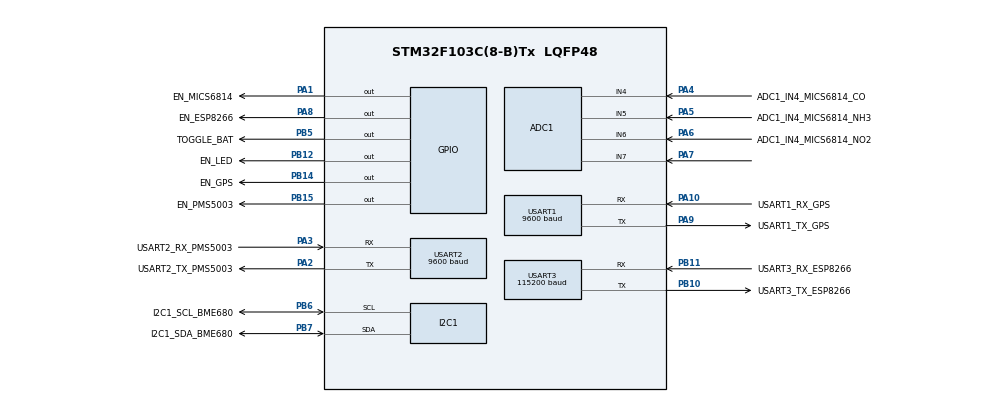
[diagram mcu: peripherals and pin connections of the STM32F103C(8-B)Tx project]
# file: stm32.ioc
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ADC1.Channel-0\#ChannelRegularConversion=ADC_CHANNEL_4
ADC1.Channel-1\#ChannelRegularConversion=ADC_CHANNEL_5
ADC1.Channel-2\#ChannelRegularConversion=ADC_CHANNEL_6
ADC1.Channel-3\#ChannelRegularConversion=ADC_CHANNEL_7
ADC1.Channel-6\#ChannelRegularConversion=ADC_CHANNEL_TEMPSENSOR
ADC1.Channel-7\#ChannelRegularConversion=ADC_CHANNEL_VREFINT
ADC1.ContinuousConvMode=ENABLE
ADC1.EnableAnalogWatchDog=false
ADC1.NbrOfConversion=6
ADC1.NbrOfConversionFlag=1
ADC1.Rank-0\#ChannelRegularConversion=1
ADC1.Rank-1\#ChannelRegularConversion=2
ADC1.Rank-2\#ChannelRegularConversion=3
ADC1.Rank-3\#ChannelRegularConversion=4
ADC1.Rank-6\#ChannelRegularConversion=5
ADC1.Rank-7\#ChannelRegularConversion=6
ADC1.SamplingTime-0\#ChannelRegularConversion=ADC_SAMPLETIME_239CYCLES_5
ADC1.SamplingTime-1\#ChannelRegularConversion=ADC_SAMPLETIME_239CYCLES_5
ADC1.SamplingTime-2\#ChannelRegularConversion=ADC_SAMPLETIME_239CYCLES_5
ADC1.SamplingTime-3\#ChannelRegularConversion=ADC_SAMPLETIME_239CYCLES_5
ADC1.SamplingTime-6\#ChannelRegularConversion=ADC_SAMPLETIME_239CYCLES_5
ADC1.SamplingTime-7\#ChannelRegularConversion=ADC_SAMPLETIME_239CYCLES_5
ADC1.master=1
Dma.ADC1.0.Direction=DMA_PERIPH_TO_MEMORY
Dma.ADC1.0.Instance=DMA1_Channel1
Dma.ADC1.0.MemDataAlignment=DMA_MDATAALIGN_WORD
Dma.ADC1.0.MemInc=DMA_MINC_ENABLE
Dma.ADC1.0.Mode=DMA_CIRCULAR
Dma.ADC1.0.PeriphDataAlignment=DMA_PDATAALIGN_HALFWORD
Dma.ADC1.0.PeriphInc=DMA_PINC_DISABLE
Dma.ADC1.0.Priority=DMA_PRIORITY_LOW
Dma.Request0=ADC1
I2C1.I2C_Mode=I2C_Standard
Mcu.Family=STM32F1
Mcu.Name=STM32F103C(8-B)Tx
Mcu.Package=LQFP48
NVIC.DMA1_Channel1_IRQn=true\:0\:0\:false\:false\:true\:false\:true
NVIC.PriorityGroup=NVIC_PRIORITYGROUP_4
NVIC.RTC_Alarm_IRQn=true\:0\:0\:false\:false\:true\:true\:true
NVIC.TIM1_UP_IRQn=true\:0\:0\:false\:false\:true\:false\:true
NVIC.TimeBase=TIM1_UP_IRQn
NVIC.TimeBaseIP=TIM1
PA1.GPIO_Label=EN_MICS6814
PA1.Signal=GPIO_Output
PA10.GPIO_Label=USART1_RX_GPS
PA10.Mode=Asynchronous
PA10.Signal=USART1_RX
PA2.GPIO_Label=USART2_TX_PMS5003
PA2.Mode=Asynchronous
PA2.Signal=USART2_TX
PA3.GPIO_Label=USART2_RX_PMS5003
PA3.Mode=Asynchronous
PA3.Signal=USART2_RX
PA4.GPIO_Label=ADC1_IN4_MICS6814_CO
PA4.Signal=ADCx_IN4
PA5.GPIO_Label=ADC1_IN4_MICS6814_NH3
PA5.Signal=ADCx_IN5
PA6.GPIO_Label=ADC1_IN4_MICS6814_NO2
PA6.Signal=ADCx_IN6
PA7.Signal=ADCx_IN7
PA8.GPIO_Label=EN_ESP8266
PA8.Signal=GPIO_Output
PA9.GPIO_Label=USART1_TX_GPS
PA9.Mode=Asynchronous
PA9.Signal=USART1_TX
PB10.GPIO_Label=USART3_TX_ESP8266
PB10.Mode=Asynchronous
PB10.Signal=USART3_TX
PB11.GPIO_Label=USART3_RX_ESP8266
PB11.Mode=Asynchronous
PB11.Signal=USART3_RX
PB12.GPIO_Label=EN_LED
PB12.PinState=GPIO_PIN_SET
PB12.Signal=GPIO_Output
PB14.GPIO_Label=EN_GPS
PB14.Signal=GPIO_Output
PB15.GPIO_Label=EN_PMS5003
PB15.Signal=GPIO_Output
PB5.GPIO_Label=TOGGLE_BAT
PB5.Signal=GPIO_Output
PB6.GPIO_Label=I2C1_SCL_BME680
PB6.Mode=I2C
PB6.Signal=I2C1_SCL
PB7.GPIO_Label=I2C1_SDA_BME680
PB7.Mode=I2C
PB7.Signal=I2C1_SDA
ProjectManager.HeapSize=0x200
ProjectManager.StackSize=0x400
ProjectManager.TargetToolchain=Makefile
RCC.AHBCLKDivider=RCC_SYSCLK_DIV2
RCC.AHBFreq_Value=4000000
RCC.APB1CLKDivider=RCC_HCLK_DIV2
RCC.APB1Freq_Value=2000000
RCC.APB1TimFreq_Value=4000000
RCC.APB2Freq_Value=4000000
RCC.APB2TimFreq_Value=4000000
RCC.HCLKFreq_Value=4000000
RCC.SYSCLKFreq_VALUE=8000000
RCC.USBFreq_Value=8000000
RTC.Format=RTC_FORMAT_BIN
SH.ADCx_IN4.0=ADC1_IN4,IN4
SH.ADCx_IN5.0=ADC1_IN5,IN5
SH.ADCx_IN6.0=ADC1_IN6,IN6
SH.ADCx_IN7.0=ADC1_IN7,IN7
USART1.BaudRate=9600
USART1.VirtualMode=VM_ASYNC
USART2.BaudRate=9600
USART2.VirtualMode=VM_ASYNC
USART3.BaudRate=115200
USART3.Mode=MODE_TX_RX
USART3.VirtualMode=VM_ASYNC
VP_ADC1_TempSens_Input.Mode=IN-TempSens
VP_ADC1_Vref_Input.Mode=IN-Vrefint
VP_RTC_No_RTC_Output.Mode=RTC_OUT_NO
VP_RTC_VS_RTC_Activate.Mode=RTC_Enabled
VP_SYS_VS_ND.Mode=No_Debug
VP_SYS_VS_tim1.Mode=TIM1
board=custom

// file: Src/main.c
/* USER CODE BEGIN Header */
/**
  ******************************************************************************
  * @file           : main.c
  * @brief          : Main program body
  ******************************************************************************
  * @attention
  *
  * <h2><center>&copy; Copyright (c) 2020 STMicroelectronics.
  * All rights reserved.</center></h2>
  *
  * This software component is licensed by ST under Ultimate Liberty license
  * SLA0044, the "License"; You may not use this file except in compliance with
  * the License. You may obtain a copy of the License at:
  *                             www.st.com/SLA0044
  *
  ******************************************************************************
  */
/* USER CODE END Header */

#include "main.h"

/* USER CODE BEGIN Includes */
#include "run.h"
/* USER CODE END Includes */

ADC_HandleTypeDef hadc1;
DMA_HandleTypeDef hdma_adc1;

I2C_HandleTypeDef hi2c1;

RTC_HandleTypeDef hrtc;

UART_HandleTypeDef huart1;
UART_HandleTypeDef huart2;
UART_HandleTypeDef huart3;

void SystemClock_Config(void);
static void MX_GPIO_Init(void);
static void MX_DMA_Init(void);
static void MX_ADC1_Init(void);
static void MX_I2C1_Init(void);
static void MX_USART1_UART_Init(void);
static void MX_USART2_UART_Init(void);
static void MX_USART3_UART_Init(void);
static void MX_RTC_Init(void);

int main(void)
{

  /* MCU Configuration--------------------------------------------------------*/

  /* Reset of all peripherals, Initializes the Flash interface and the Systick. */
  HAL_Init();

  /* Configure the system clock */
  SystemClock_Config();

  /* Initialize all configured peripherals */
  MX_GPIO_Init();
  MX_DMA_Init();
  MX_ADC1_Init();
  MX_I2C1_Init();
  MX_USART1_UART_Init();
  MX_USART2_UART_Init();
  MX_USART3_UART_Init();
  MX_RTC_Init();

  /* Infinite loop */
  /* USER CODE BEGIN WHILE */
  setup();
  while (1)
  {
    loop();
    /* USER CODE END WHILE */

  }
}

void SystemClock_Config(void)
{
  LL_FLASH_SetLatency(LL_FLASH_LATENCY_0);

  if(LL_FLASH_GetLatency() != LL_FLASH_LATENCY_0)
  {
    Error_Handler();
  }
  LL_RCC_HSI_SetCalibTrimming(16);
  LL_RCC_HSI_Enable();

   /* Wait till HSI is ready */
  while(LL_RCC_HSI_IsReady() != 1)
  {

  }
  LL_RCC_LSI_Enable();

   /* Wait till LSI is ready */
  while(LL_RCC_LSI_IsReady() != 1)
  {

  }
  LL_PWR_EnableBkUpAccess();
  LL_RCC_ForceBackupDomainReset();
  LL_RCC_ReleaseBackupDomainReset();
  LL_RCC_SetRTCClockSource(LL_RCC_RTC_CLKSOURCE_LSI);
  LL_RCC_EnableRTC();
  LL_RCC_SetAHBPrescaler(LL_RCC_SYSCLK_DIV_2);
  LL_RCC_SetAPB1Prescaler(LL_RCC_APB1_DIV_2);
  LL_RCC_SetAPB2Prescaler(LL_RCC_APB2_DIV_1);
  LL_RCC_SetSysClkSource(LL_RCC_SYS_CLKSOURCE_HSI);

   /* Wait till System clock is ready */
  while(LL_RCC_GetSysClkSource() != LL_RCC_SYS_CLKSOURCE_STATUS_HSI)
  {

  }
  LL_SetSystemCoreClock(4000000);

   /* Update the time base */
  if (HAL_InitTick (TICK_INT_PRIORITY) != HAL_OK)
  {
    Error_Handler();
  };
  LL_RCC_SetADCClockSource(LL_RCC_ADC_CLKSRC_PCLK2_DIV_2);
}

static void MX_ADC1_Init(void)
{

  ADC_ChannelConfTypeDef sConfig = {0};

  /** Common config
  */
  hadc1.Instance = ADC1;
  hadc1.Init.ScanConvMode = ADC_SCAN_ENABLE;
  hadc1.Init.ContinuousConvMode = ENABLE;
  hadc1.Init.DiscontinuousConvMode = DISABLE;
  hadc1.Init.ExternalTrigConv = ADC_SOFTWARE_START;
  hadc1.Init.DataAlign = ADC_DATAALIGN_RIGHT;
  hadc1.Init.NbrOfConversion = 6;
  if (HAL_ADC_Init(&hadc1) != HAL_OK)
  {
    Error_Handler();
  }
  /** Configure Regular Channel
  */
  sConfig.Channel = ADC_CHANNEL_4;
  sConfig.Rank = ADC_REGULAR_RANK_1;
  sConfig.SamplingTime = ADC_SAMPLETIME_239CYCLES_5;
  if (HAL_ADC_ConfigChannel(&hadc1, &sConfig) != HAL_OK)
  {
    Error_Handler();
  }
  /** Configure Regular Channel
  */
  sConfig.Channel = ADC_CHANNEL_5;
  sConfig.Rank = ADC_REGULAR_RANK_2;
  if (HAL_ADC_ConfigChannel(&hadc1, &sConfig) != HAL_OK)
  {
    Error_Handler();
  }
  /** Configure Regular Channel
  */
  sConfig.Channel = ADC_CHANNEL_6;
  sConfig.Rank = ADC_REGULAR_RANK_3;
  if (HAL_ADC_ConfigChannel(&hadc1, &sConfig) != HAL_OK)
  {
    Error_Handler();
  }
  /** Configure Regular Channel
  */
  sConfig.Channel = ADC_CHANNEL_7;
  sConfig.Rank = ADC_REGULAR_RANK_4;
  if (HAL_ADC_ConfigChannel(&hadc1, &sConfig) != HAL_OK)
  {
    Error_Handler();
  }
  /** Configure Regular Channel
  */
  sConfig.Channel = ADC_CHANNEL_TEMPSENSOR;
  sConfig.Rank = ADC_REGULAR_RANK_5;
  if (HAL_ADC_ConfigChannel(&hadc1, &sConfig) != HAL_OK)
  {
    Error_Handler();
  }
  /** Configure Regular Channel
  */
  sConfig.Channel = ADC_CHANNEL_VREFINT;
  sConfig.Rank = ADC_REGULAR_RANK_6;
  if (HAL_ADC_ConfigChannel(&hadc1, &sConfig) != HAL_OK)
  {
    Error_Handler();
  }

}

static void MX_I2C1_Init(void)
{

  hi2c1.Instance = I2C1;
  hi2c1.Init.ClockSpeed = 100000;
  hi2c1.Init.DutyCycle = I2C_DUTYCYCLE_2;
  hi2c1.Init.OwnAddress1 = 0;
  hi2c1.Init.AddressingMode = I2C_ADDRESSINGMODE_7BIT;
  hi2c1.Init.DualAddressMode = I2C_DUALADDRESS_DISABLE;
  hi2c1.Init.OwnAddress2 = 0;
  hi2c1.Init.GeneralCallMode = I2C_GENERALCALL_DISABLE;
  hi2c1.Init.NoStretchMode = I2C_NOSTRETCH_DISABLE;
  if (HAL_I2C_Init(&hi2c1) != HAL_OK)
  {
    Error_Handler();
  }

}

static void MX_RTC_Init(void)
{

  RTC_TimeTypeDef sTime = {0};
  RTC_DateTypeDef DateToUpdate = {0};

  /** Initialize RTC Only
  */
  hrtc.Instance = RTC;
  hrtc.Init.AsynchPrediv = RTC_AUTO_1_SECOND;
  hrtc.Init.OutPut = RTC_OUTPUTSOURCE_NONE;
  if (HAL_RTC_Init(&hrtc) != HAL_OK)
  {
    Error_Handler();
  }

  /** Initialize RTC and set the Time and Date
  */
  sTime.Hours = 0;
  sTime.Minutes = 0;
  sTime.Seconds = 0;

  if (HAL_RTC_SetTime(&hrtc, &sTime, RTC_FORMAT_BIN) != HAL_OK)
  {
    Error_Handler();
  }
  DateToUpdate.WeekDay = RTC_WEEKDAY_MONDAY;
  DateToUpdate.Month = RTC_MONTH_JANUARY;
  DateToUpdate.Date = 1;
  DateToUpdate.Year = 0;

  if (HAL_RTC_SetDate(&hrtc, &DateToUpdate, RTC_FORMAT_BIN) != HAL_OK)
  {
    Error_Handler();
  }

}

static void MX_USART1_UART_Init(void)
{

  huart1.Instance = USART1;
  huart1.Init.BaudRate = 9600;
  huart1.Init.WordLength = UART_WORDLENGTH_8B;
  huart1.Init.StopBits = UART_STOPBITS_1;
  huart1.Init.Parity = UART_PARITY_NONE;
  huart1.Init.Mode = UART_MODE_TX_RX;
  huart1.Init.HwFlowCtl = UART_HWCONTROL_NONE;
  huart1.Init.OverSampling = UART_OVERSAMPLING_16;
  if (HAL_UART_Init(&huart1) != HAL_OK)
  {
    Error_Handler();
  }

}

static void MX_USART2_UART_Init(void)
{

  huart2.Instance = USART2;
  huart2.Init.BaudRate = 9600;
  huart2.Init.WordLength = UART_WORDLENGTH_8B;
  huart2.Init.StopBits = UART_STOPBITS_1;
  huart2.Init.Parity = UART_PARITY_NONE;
  huart2.Init.Mode = UART_MODE_TX_RX;
  huart2.Init.HwFlowCtl = UART_HWCONTROL_NONE;
  huart2.Init.OverSampling = UART_OVERSAMPLING_16;
  if (HAL_UART_Init(&huart2) != HAL_OK)
  {
    Error_Handler();
  }

}

static void MX_USART3_UART_Init(void)
{

  huart3.Instance = USART3;
  huart3.Init.BaudRate = 115200;
  huart3.Init.WordLength = UART_WORDLENGTH_8B;
  huart3.Init.StopBits = UART_STOPBITS_1;
  huart3.Init.Parity = UART_PARITY_NONE;
  huart3.Init.Mode = UART_MODE_TX_RX;
  huart3.Init.HwFlowCtl = UART_HWCONTROL_NONE;
  huart3.Init.OverSampling = UART_OVERSAMPLING_16;
  if (HAL_UART_Init(&huart3) != HAL_OK)
  {
    Error_Handler();
  }

}

static void MX_DMA_Init(void)
{

  /* DMA controller clock enable */
  __HAL_RCC_DMA1_CLK_ENABLE();

  /* DMA interrupt init */
  /* DMA1_Channel1_IRQn interrupt configuration */
  HAL_NVIC_SetPriority(DMA1_Channel1_IRQn, 0, 0);
  HAL_NVIC_EnableIRQ(DMA1_Channel1_IRQn);

}

static void MX_GPIO_Init(void)
{
  GPIO_InitTypeDef GPIO_InitStruct = {0};

  /* GPIO Ports Clock Enable */
  __HAL_RCC_GPIOC_CLK_ENABLE();
  __HAL_RCC_GPIOD_CLK_ENABLE();
  __HAL_RCC_GPIOA_CLK_ENABLE();
  __HAL_RCC_GPIOB_CLK_ENABLE();

  /*Configure GPIO pin Output Level */
  HAL_GPIO_WritePin(GPIOA, EN_MICS6814_Pin|EN_ESP8266_Pin, GPIO_PIN_RESET);

  /*Configure GPIO pin Output Level */
  HAL_GPIO_WritePin(EN_LED_GPIO_Port, EN_LED_Pin, GPIO_PIN_SET);

  /*Configure GPIO pin Output Level */
  HAL_GPIO_WritePin(GPIOB, EN_GPS_Pin|EN_PMS5003_Pin|TOGGLE_BAT_Pin, GPIO_PIN_RESET);

  /*Configure GPIO pins : PC13 PC14 PC15 */
  GPIO_InitStruct.Pin = GPIO_PIN_13|GPIO_PIN_14|GPIO_PIN_15;
  GPIO_InitStruct.Mode = GPIO_MODE_ANALOG;
  HAL_GPIO_Init(GPIOC, &GPIO_InitStruct);

  /*Configure GPIO pins : PD0 PD1 */
  GPIO_InitStruct.Pin = GPIO_PIN_0|GPIO_PIN_1;
  GPIO_InitStruct.Mode = GPIO_MODE_ANALOG;
  HAL_GPIO_Init(GPIOD, &GPIO_InitStruct);

  /*Configure GPIO pins : PA0 PA11 PA12 PA13
                           PA14 PA15 */
  GPIO_InitStruct.Pin = GPIO_PIN_0|GPIO_PIN_11|GPIO_PIN_12|GPIO_PIN_13
                          |GPIO_PIN_14|GPIO_PIN_15;
  GPIO_InitStruct.Mode = GPIO_MODE_ANALOG;
  HAL_GPIO_Init(GPIOA, &GPIO_InitStruct);

  /*Configure GPIO pins : EN_MICS6814_Pin EN_ESP8266_Pin */
  GPIO_InitStruct.Pin = EN_MICS6814_Pin|EN_ESP8266_Pin;
  GPIO_InitStruct.Mode = GPIO_MODE_OUTPUT_PP;
  GPIO_InitStruct.Pull = GPIO_NOPULL;
  GPIO_InitStruct.Speed = GPIO_SPEED_FREQ_LOW;
  HAL_GPIO_Init(GPIOA, &GPIO_InitStruct);

  /*Configure GPIO pins : PB0 PB1 PB2 PB13
                           PB3 PB4 PB8 PB9 */
  GPIO_InitStruct.Pin = GPIO_PIN_0|GPIO_PIN_1|GPIO_PIN_2|GPIO_PIN_13
                          |GPIO_PIN_3|GPIO_PIN_4|GPIO_PIN_8|GPIO_PIN_9;
  GPIO_InitStruct.Mode = GPIO_MODE_ANALOG;
  HAL_GPIO_Init(GPIOB, &GPIO_InitStruct);

  /*Configure GPIO pins : EN_LED_Pin EN_GPS_Pin EN_PMS5003_Pin TOGGLE_BAT_Pin */
  GPIO_InitStruct.Pin = EN_LED_Pin|EN_GPS_Pin|EN_PMS5003_Pin|TOGGLE_BAT_Pin;
  GPIO_InitStruct.Mode = GPIO_MODE_OUTPUT_PP;
  GPIO_InitStruct.Pull = GPIO_NOPULL;
  GPIO_InitStruct.Speed = GPIO_SPEED_FREQ_LOW;
  HAL_GPIO_Init(GPIOB, &GPIO_InitStruct);

  /*Configure peripheral I/O remapping */
  __HAL_AFIO_REMAP_PD01_ENABLE();

}

 /**
  * @brief  Period elapsed callback in non blocking mode
  * @note   This function is called  when TIM1 interrupt took place, inside
  * HAL_TIM_IRQHandler(). It makes a direct call to HAL_IncTick() to increment
  * a global variable "uwTick" used as application time base.
  * @param  htim : TIM handle
  * @retval None
  */
void HAL_TIM_PeriodElapsedCallback(TIM_HandleTypeDef *htim)
{
  if (htim->Instance == TIM1) {
    HAL_IncTick();
  }
}

void Error_Handler(void)
{
}

/************************ (C) COPYRIGHT STMicroelectronics *****END OF FILE****/
